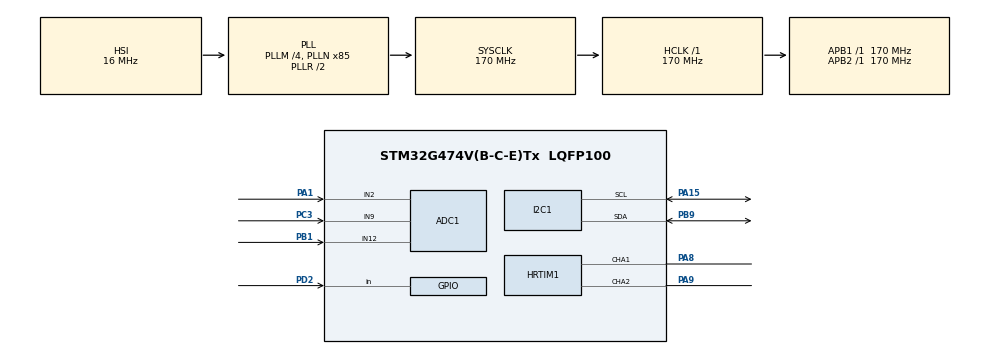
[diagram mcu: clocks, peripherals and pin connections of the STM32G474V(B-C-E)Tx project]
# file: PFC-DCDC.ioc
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ADC1.Channel-0\#ChannelRegularConversion=ADC_CHANNEL_12
ADC1.Channel-1\#ChannelRegularConversion=ADC_CHANNEL_2
ADC1.Channel-2\#ChannelRegularConversion=ADC_CHANNEL_2
ADC1.ContinuousConvMode=ENABLE
ADC1.DMAContinuousRequests=ENABLE
ADC1.NbrOfConversion=3
ADC1.NbrOfConversionFlag=1
ADC1.OffsetNumber-0\#ChannelRegularConversion=ADC_OFFSET_NONE
ADC1.OffsetNumber-1\#ChannelRegularConversion=ADC_OFFSET_NONE
ADC1.OffsetNumber-2\#ChannelRegularConversion=ADC_OFFSET_NONE
ADC1.Rank-0\#ChannelRegularConversion=1
ADC1.Rank-1\#ChannelRegularConversion=2
ADC1.Rank-2\#ChannelRegularConversion=3
ADC1.SamplingTime-0\#ChannelRegularConversion=ADC_SAMPLETIME_92CYCLES_5
ADC1.SamplingTime-1\#ChannelRegularConversion=ADC_SAMPLETIME_92CYCLES_5
ADC1.SamplingTime-2\#ChannelRegularConversion=ADC_SAMPLETIME_92CYCLES_5
ADC1.master=1
Dma.ADC1.0.Direction=DMA_PERIPH_TO_MEMORY
Dma.ADC1.0.EventEnable=DISABLE
Dma.ADC1.0.Instance=DMA1_Channel1
Dma.ADC1.0.MemDataAlignment=DMA_MDATAALIGN_HALFWORD
Dma.ADC1.0.MemInc=DMA_MINC_ENABLE
Dma.ADC1.0.Mode=DMA_CIRCULAR
Dma.ADC1.0.PeriphDataAlignment=DMA_PDATAALIGN_HALFWORD
Dma.ADC1.0.PeriphInc=DMA_PINC_DISABLE
Dma.ADC1.0.Polarity=HAL_DMAMUX_REQ_GEN_RISING
Dma.ADC1.0.Priority=DMA_PRIORITY_LOW
Dma.ADC1.0.RequestNumber=1
Dma.ADC1.0.SignalID=NONE
Dma.ADC1.0.SyncEnable=DISABLE
Dma.ADC1.0.SyncPolarity=HAL_DMAMUX_SYNC_NO_EVENT
Dma.ADC1.0.SyncRequestNumber=1
Dma.ADC1.0.SyncSignalID=NONE
Dma.Request0=ADC1
HRTIM1.CompareUnit1-Output_TA1TA2=HRTIM_COMPAREUNIT_1
HRTIM1.CompareValue1-Output_TA1TA2=1088
HRTIM1.DeadTimeInsertion-Output_TA1TA2=HRTIM_TIMDEADTIMEINSERTION_ENABLED
HRTIM1.FallingValue-Output_TA1TA2=408
HRTIM1.FaultLevel1-Output_TA1TA2=HRTIM_OUTPUTFAULTLEVEL_INACTIVE
HRTIM1.FaultLevel2-Output_TA1TA2=HRTIM_OUTPUTFAULTLEVEL_INACTIVE
HRTIM1.HRTIMInterruptResquests1=HRTIM_IT_NONE
HRTIM1.NumberResetSource1-Output_TA1TA2=1
HRTIM1.NumberSetSource1-Output_TA1TA2=1
HRTIM1.Periode_TA=0xD480
HRTIM1.PreloadEnable-Output_TA1TA2=HRTIM_PRELOAD_ENABLED
HRTIM1.PrescalerRatio_TA=HRTIM_PRESCALERRATIO_MUL16
HRTIM1.ResetOutput1_Source1-Output_TA1TA2=HRTIM_OUTPUTRESET_TIMPER
HRTIM1.RisingValue-Output_TA1TA2=408
HRTIM1.SetOutput1_Source1-Output_TA1TA2=HRTIM_OUTPUTSET_TIMCMP1
I2C1.Timing=0x40B285C2
Mcu.Family=STM32G4
Mcu.Name=STM32G474V(B-C-E)Tx
Mcu.Package=LQFP100
NVIC.DMA1_Channel1_IRQn=true\:0\:0\:false\:false\:true\:false\:true\:true
NVIC.PriorityGroup=NVIC_PRIORITYGROUP_4
PA1.Mode=IN2-Single-Ended
PA1.Signal=ADC1_IN2
PA13.Mode=Serial_Wire
PA13.Signal=SYS_JTMS-SWDIO
PA14.Mode=Serial_Wire
PA14.Signal=SYS_JTCK-SWCLK
PA15.GPIO_Pu=GPIO_PULLUP
PA15.Mode=I2C
PA15.Signal=I2C1_SCL
PA8.Mode=Output_TA1TA2
PA8.Signal=HRTIM1_CHA1
PA9.Mode=Output_TA1TA2
PA9.Signal=HRTIM1_CHA2
PB1.Mode=IN12-Single-Ended
PB1.Signal=ADC1_IN12
PB9.GPIO_FM9=__NULL
PB9.GPIO_Pu=GPIO_PULLUP
PB9.Mode=I2C
PB9.Signal=I2C1_SDA
PC3.Mode=IN9-Single-Ended
PC3.Signal=ADC1_IN9
PD2.GPIO_PuPd=GPIO_PULLUP
PD2.Signal=GPIO_Input
PF0-OSC_IN.Mode=HSE-External-Oscillator
PF0-OSC_IN.Signal=RCC_OSC_IN
PF1-OSC_OUT.Mode=HSE-External-Oscillator
PF1-OSC_OUT.Signal=RCC_OSC_OUT
ProjectManager.HeapSize=0x200
ProjectManager.StackSize=0x400
ProjectManager.TargetToolchain=CMake
RCC.ADC12Freq_Value=170000000
RCC.ADC345Freq_Value=170000000
RCC.AHBFreq_Value=170000000
RCC.APB1Freq_Value=170000000
RCC.APB1TimFreq_Value=170000000
RCC.APB2Freq_Value=170000000
RCC.APB2TimFreq_Value=170000000
RCC.CortexFreq_Value=170000000
RCC.EXTERNAL_CLOCK_VALUE=12288000
RCC.HCLKFreq_Value=170000000
RCC.HSE_VALUE=8000000
RCC.HSI48_VALUE=48000000
RCC.HSI_VALUE=16000000
RCC.LSE_VALUE=32768
RCC.PLLM=RCC_PLLM_DIV4
RCC.PLLN=85
RCC.SYSCLKFreq_VALUE=170000000
RCC.SYSCLKSource=RCC_SYSCLKSOURCE_PLLCLK
RCC.USBFreq_Value=170000000
RCC.VCOOutputFreq_Value=340000000
SYS.VoltageScaling=SYSCFG_VREFBUF_VOLTAGE_SCALE2
VP_SYS_VS_DBSignals.Mode=DisableDeadBatterySignals
VREF+.Mode=InternalMode
VREF+.Signal=VREFBUF_OUT
board=custom

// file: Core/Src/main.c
/* USER CODE BEGIN Header */
/**
  ******************************************************************************
  * @file           : main.c
  * @brief          : Main program body
  ******************************************************************************
  * @attention
  *
  * Copyright (c) 2026 STMicroelectronics.
  * All rights reserved.
  *
  * This software is licensed under terms that can be found in the LICENSE file
  * in the root directory of this software component.
  * If no LICENSE file comes with this software, it is provided AS-IS.
  *
  ******************************************************************************
  */
/* USER CODE END Header */
#include "main.h"
#include "adc.h"
#include "dma.h"
#include "hrtim.h"
#include "i2c.h"
#include "gpio.h"

/* USER CODE BEGIN Includes */
#include "pfc_app.h"
#include "pfc_measure.h"
#include "pfc_pwm.h"

/* USER CODE END Includes */

void SystemClock_Config(void);

int main(void)
{

  /* MCU Configuration--------------------------------------------------------*/

  /* Reset of all peripherals, Initializes the Flash interface and the Systick. */
  HAL_Init();

  /* Configure the system clock */
  SystemClock_Config();

  /* Initialize all configured peripherals */
  MX_GPIO_Init();
  MX_DMA_Init();
  MX_ADC1_Init();
  MX_HRTIM1_Init();
  MX_I2C1_Init();
  /* USER CODE BEGIN 2 */
  PFC_Measure_Start();
  PFC_Measure_CalibrateCurrentZero();
  PFC_PWM_InitSafe();

  /* USER CODE END 2 */

  /* Infinite loop */
  while (1)
  {

    /* USER CODE BEGIN 3 */
    PFC_Measure_Update();
    PFC_App_Task();
  }
  /* USER CODE END 3 */
}

void SystemClock_Config(void)
{
  RCC_OscInitTypeDef RCC_OscInitStruct = {0};
  RCC_ClkInitTypeDef RCC_ClkInitStruct = {0};

  /** Configure the main internal regulator output voltage
  */
  HAL_PWREx_ControlVoltageScaling(PWR_REGULATOR_VOLTAGE_SCALE1_BOOST);

  /** Initializes the RCC Oscillators according to the specified parameters
  * in the RCC_OscInitTypeDef structure.
  */
  RCC_OscInitStruct.OscillatorType = RCC_OSCILLATORTYPE_HSI;
  RCC_OscInitStruct.HSIState = RCC_HSI_ON;
  RCC_OscInitStruct.HSICalibrationValue = RCC_HSICALIBRATION_DEFAULT;
  RCC_OscInitStruct.PLL.PLLState = RCC_PLL_ON;
  RCC_OscInitStruct.PLL.PLLSource = RCC_PLLSOURCE_HSI;
  RCC_OscInitStruct.PLL.PLLM = RCC_PLLM_DIV4;
  RCC_OscInitStruct.PLL.PLLN = 85;
  RCC_OscInitStruct.PLL.PLLP = RCC_PLLP_DIV2;
  RCC_OscInitStruct.PLL.PLLQ = RCC_PLLQ_DIV2;
  RCC_OscInitStruct.PLL.PLLR = RCC_PLLR_DIV2;
  if (HAL_RCC_OscConfig(&RCC_OscInitStruct) != HAL_OK)
  {
    Error_Handler();
  }

  /** Initializes the CPU, AHB and APB buses clocks
  */
  RCC_ClkInitStruct.ClockType = RCC_CLOCKTYPE_HCLK|RCC_CLOCKTYPE_SYSCLK
                              |RCC_CLOCKTYPE_PCLK1|RCC_CLOCKTYPE_PCLK2;
  RCC_ClkInitStruct.SYSCLKSource = RCC_SYSCLKSOURCE_PLLCLK;
  RCC_ClkInitStruct.AHBCLKDivider = RCC_SYSCLK_DIV1;
  RCC_ClkInitStruct.APB1CLKDivider = RCC_HCLK_DIV1;
  RCC_ClkInitStruct.APB2CLKDivider = RCC_HCLK_DIV1;

  if (HAL_RCC_ClockConfig(&RCC_ClkInitStruct, FLASH_LATENCY_4) != HAL_OK)
  {
    Error_Handler();
  }
}

void Error_Handler(void)
{
  __disable_irq();
  while (1)
  {
  }
}
